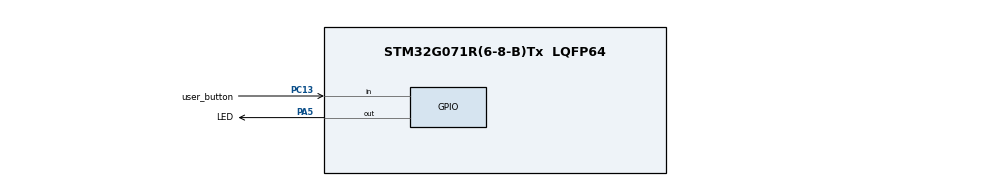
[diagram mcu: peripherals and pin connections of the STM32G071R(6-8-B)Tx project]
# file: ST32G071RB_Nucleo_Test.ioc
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Mcu.Family=STM32G0
Mcu.Name=STM32G071R(6-8-B)Tx
Mcu.Package=LQFP64
PA5.GPIO_Label=LED
PA5.Signal=GPIO_Output
PC13.GPIO_Label=user_button
PC13.Signal=GPIO_Input
ProjectManager.HeapSize=0x200
ProjectManager.StackSize=0x400
ProjectManager.TargetToolchain=STM32CubeIDE
RCC.AHBFreq_Value=16000000
RCC.CortexFreq_Value=16000000
RCC.EXTERNAL_CLOCK_VALUE=48000
RCC.HCLKFreq_Value=16000000
RCC.HSE_VALUE=8000000
RCC.HSI_VALUE=16000000
RCC.LSE_VALUE=32768
RCC.SYSCLKFreq_VALUE=16000000
RCC.VCOOutputFreq_Value=128000000
board=custom

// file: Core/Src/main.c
/* USER CODE BEGIN Header */
/**
  ******************************************************************************
  * @file           : main.c
  * @brief          : Main program body
  ******************************************************************************
  * @attention
  *
  * Copyright (c) 2024 STMicroelectronics.
  * All rights reserved.
  *
  * This software is licensed under terms that can be found in the LICENSE file
  * in the root directory of this software component.
  * If no LICENSE file comes with this software, it is provided AS-IS.
  *
  ******************************************************************************
  */
/* USER CODE END Header */
#include "main.h"

/* USER CODE BEGIN Includes */

#include "keyboard.h"
/* USER CODE END Includes */

void SystemClock_Config(void);
static void MX_GPIO_Init(void);

int main(void)
{

  /* MCU Configuration--------------------------------------------------------*/

  /* Reset of all peripherals, Initializes the Flash interface and the Systick. */
  LL_APB2_GRP1_EnableClock(LL_APB2_GRP1_PERIPH_SYSCFG);
  LL_APB1_GRP1_EnableClock(LL_APB1_GRP1_PERIPH_PWR);

  /* SysTick_IRQn interrupt configuration */
  NVIC_SetPriority(SysTick_IRQn, 3);

  /* Configure the system clock */
  SystemClock_Config();

  /* Initialize all configured peripherals */
  MX_GPIO_Init();
  /* USER CODE BEGIN 2 */

  init_keyboard();
  LL_SYSTICK_EnableIT();

  // LL_GPIO_SetOutputPin(LED_GPIO_Port,LED_Pin);
  /* USER CODE END 2 */

  /* Infinite loop */
  /* USER CODE BEGIN WHILE */
  while (1)
  {

    check_keyboard();
    /* USER CODE END WHILE */

  }
}

void SystemClock_Config(void)
{
  /* HSI configuration and activation */
  LL_RCC_HSI_Enable();
  while(LL_RCC_HSI_IsReady() != 1)
  {
  }

  /* Set AHB prescaler*/
  LL_RCC_SetAHBPrescaler(LL_RCC_SYSCLK_DIV_1);

  /* Sysclk activation on the HSI */
  LL_RCC_SetSysClkSource(LL_RCC_SYS_CLKSOURCE_HSI);
  while(LL_RCC_GetSysClkSource() != LL_RCC_SYS_CLKSOURCE_STATUS_HSI)
  {
  }

  /* Set APB1 prescaler*/
  LL_RCC_SetAPB1Prescaler(LL_RCC_APB1_DIV_1);
  LL_Init1msTick(16000000);
  /* Update CMSIS variable (which can be updated also through SystemCoreClockUpdate function) */
  LL_SetSystemCoreClock(16000000);
}

static void MX_GPIO_Init(void)
{
  LL_GPIO_InitTypeDef GPIO_InitStruct = {0};

  /* GPIO Ports Clock Enable */
  LL_IOP_GRP1_EnableClock(LL_IOP_GRP1_PERIPH_GPIOC);
  LL_IOP_GRP1_EnableClock(LL_IOP_GRP1_PERIPH_GPIOA);

  /**/
  LL_GPIO_ResetOutputPin(LED_GPIO_Port, LED_Pin);

  /**/
  GPIO_InitStruct.Pin = user_button_Pin;
  GPIO_InitStruct.Mode = LL_GPIO_MODE_INPUT;
  GPIO_InitStruct.Pull = LL_GPIO_PULL_NO;
  LL_GPIO_Init(user_button_GPIO_Port, &GPIO_InitStruct);

  /**/
  GPIO_InitStruct.Pin = LED_Pin;
  GPIO_InitStruct.Mode = LL_GPIO_MODE_OUTPUT;
  GPIO_InitStruct.Speed = LL_GPIO_SPEED_FREQ_LOW;
  GPIO_InitStruct.OutputType = LL_GPIO_OUTPUT_PUSHPULL;
  GPIO_InitStruct.Pull = LL_GPIO_PULL_NO;
  LL_GPIO_Init(LED_GPIO_Port, &GPIO_InitStruct);

}

void Error_Handler(void)
{
  __disable_irq();
  while (1)
  {
  }
}
